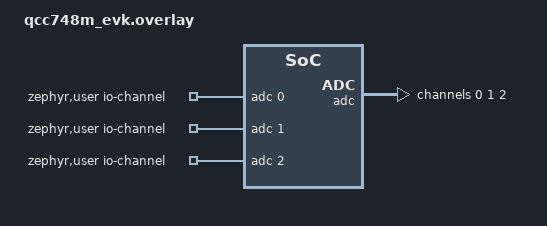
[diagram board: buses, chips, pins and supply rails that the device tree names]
/*
 * Copyright (c) 2026 Qualcomm Technologies, Inc. and/or its subsidiaries
 * SPDX-License-Identifier: BSD-3-Clause
 *
 * qcc748m_evk board overlay for zephyr/samples/drivers/adc/adc_dt.
 * Ported from the v4.1 QCC74x fork's boards/qcc748m_evk.overlay +
 * qcc74xm_evk_common.dtsi (inlined here). Provides the /zephyr,user
 * io-channels the sample's filter requires plus a 3-channel ADC config.
 *
 * Inject with west (bypasses the sample's non-qcc74x platform_allow):
 *   west build -p always -b qcc748m_evk/qcc748 -d C:/b \
 *     zephyr/samples/drivers/adc/adc_dt \
 *     -- -DDTC_OVERLAY_FILE=<abs>/board_overlays/adc_dt/qcc748m_evk.overlay
 */

/ {
	zephyr,user {
		io-channels = <&adc 0>, <&adc 1>, <&adc 2>;
	};
	aliases {
		adc0 = &adc;
	};
};

&pinctrl {
	adc_default: adc_default {
		group1 {
			pinmux = <GPIO27_ADC_CH10>,
				 <GPIO20_ADC_CH0>;
			input-enable;
			input-schmitt-enable;
		};
	};
};

&adc {
	status = "okay";
	pinctrl-0 = <&adc_default>;
	pinctrl-names = "default";

	#address-cells = <1>;
	#size-cells = <0>;

	channel@0 {
		reg = <0>;
		zephyr,gain = "ADC_GAIN_1";
		zephyr,reference = "ADC_REF_INTERNAL";
		zephyr,acquisition-time = <ADC_ACQ_TIME_DEFAULT>;
		zephyr,input-positive = <ADC_CHANNEL_GND>;
		zephyr,input-negative = <ADC_CHANNEL_10>;
		zephyr,resolution = <16>;
	};

	channel@1 {
		reg = <1>;
		zephyr,gain = "ADC_GAIN_1";
		zephyr,reference = "ADC_REF_INTERNAL";
		zephyr,acquisition-time = <ADC_ACQ_TIME_DEFAULT>;
		zephyr,input-positive = <ADC_CHANNEL_10>;
		zephyr,resolution = <14>;
	};

	channel@2 {
		reg = <2>;
		zephyr,gain = "ADC_GAIN_1";
		zephyr,reference = "ADC_REF_INTERNAL";
		zephyr,acquisition-time = <ADC_ACQ_TIME_DEFAULT>;
		zephyr,input-positive = <ADC_CHANNEL_0>;
		zephyr,resolution = <16>;
	};
};
